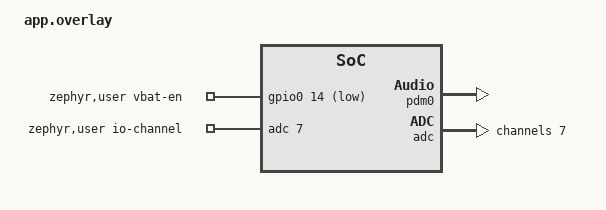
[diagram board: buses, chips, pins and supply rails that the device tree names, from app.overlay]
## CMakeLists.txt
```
cmake_minimum_required(VERSION 3.20.0)
find_package(Zephyr REQUIRED HINTS $ENV{ZEPHYR_BASE})
project(meowtion_collar)

target_sources(app PRIVATE
    src/main.c
    src/ble.c
    src/audio.c
    src/streaming.c
    src/battery.c
    src/classifier.c
    src/activity.c              # rules-based activity gate (cascade tier 0): low-power rest gating
    src/production.c            # production mode: real on-device classification -> telemetry
    src/imu.c
    src/ota.c                   # Phase-3 OTA model delivery: BLE -> flash slots -> XIP load
    src/tflm_classifier.cpp)   # TFLM inference backend , strong overrides of the cascade hooks
target_include_directories(app PRIVATE ${CMAKE_CURRENT_SOURCE_DIR}/../common)   # shared meow_protocol.h
```

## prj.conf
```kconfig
# Meowtion collar (Zephyr / nRF Connect SDK)
CONFIG_BT=y
CONFIG_BT_PERIPHERAL=y            # connectable: a central (station/phone) connects to stream audio
CONFIG_BT_DEVICE_NAME="Meowtion Collar"
CONFIG_LOG=y

# Throughput for the audio notify stream: bigger ATT MTU + link-layer data length.
CONFIG_BT_L2CAP_TX_MTU=247
CONFIG_BT_BUF_ACL_TX_SIZE=251
CONFIG_BT_BUF_ACL_RX_SIZE=251
CONFIG_BT_CTLR_DATA_LENGTH_MAX=251
CONFIG_BT_GATT_AUTO_UPDATE_MTU=y
# The 8 kHz stream is ~17 KB/s. At 1 packet per connection event the link sat just under that and
# slowly dropped frames. Queue several packets per event (more TX buffers; the controller's event-RX
# count must stay above the ACL-TX count) and enable 2M PHY (half the airtime per packet) so the
# drain rate clears the audio rate with margin. Station requests 2M after connecting.
CONFIG_BT_BUF_ACL_TX_COUNT=10
CONFIG_BT_BUF_EVT_RX_COUNT=12
CONFIG_BT_CTLR_PHY_2M=y

# --- BLE link security (LE Secure Connections) ---
# The audio + OTA characteristics require an ENCRYPTED link (see ble.c/ota.c PERM_*_ENCRYPT), so an
# unpaired central cannot stream audio or push a model. NON-BONDABLE on purpose: a battery collar
# reboots often, so a stored bond would go stale and pairing would then fail until both sides re-sync.
# Pairing fresh each connection (a sub-second ECDH; SMP pulls in CONFIG_BT_ECC / P-256) stores nothing,
# so there is no bond state to go stale. Just Works today; step 2b adds a USB-provisioned OOB secret
# that authenticates each pairing (MITM protection).
CONFIG_BT_SMP=y
CONFIG_BT_BONDABLE=n

# USB CDC ACM console + the MEOW> id banner, on the LEGACY USB device stack.
# The board's default backend uses the new (NEXT) USB stack, whose CDC console doesn't deliver
# console output on this build (the port enumerates but stays silent). So we disable the board
# backend and bring up a single legacy CDC ACM ourselves (see app.overlay + usb_enable() in
# main). The legacy stack's console poll_out buffers reliably, which is what we need.
CONFIG_BOARD_SERIAL_BACKEND_CDC_ACM=n
CONFIG_USB_DEVICE_STACK=y
CONFIG_USB_DEVICE_PRODUCT="Meowtion Collar"
CONFIG_SERIAL=y
CONFIG_UART_LINE_CTRL=y
CONFIG_CONSOLE=y
CONFIG_UART_CONSOLE=y

# Real battery sensing: ADC (SAADC) on AIN7 + GPIO to gate the divider (see app.overlay).
CONFIG_ADC=y
CONFIG_GPIO=y

# Onboard PDM microphone (XIAO Sense) for audio capture.
CONFIG_AUDIO=y
CONFIG_AUDIO_DMIC=y

# Onboard IMU (LSM6DS3TR-C on i2c0, driven by Zephyr's lsm6dsl driver). Sampled alongside each
# audio clip to produce paired training data, and fed to the classifier cascade. Polled (no trigger).
CONFIG_I2C=y
CONFIG_SENSOR=y
CONFIG_LSM6DSL=y
# The IMU sensor node is marked zephyr,deferred-init (overlay) so its init runs from imu_init()
# in main , after the power rail is up , instead of at boot where it raced the rail and failed.

# On-collar inference: TensorFlow Lite Micro (C++17). No model is compiled in , models are loaded at
# runtime (model_loader.h), so present()==false until then and the cascade runs model-free. TFLM's
# Kconfig selects REQUIRES_FULL_LIBCPP. CMSIS-NN kernels are optimized Cortex-M ops (cmsis-nn is
# allowlisted in the NCS manifest) , they accelerate Conv/FullyConnected/Pooling/Softmax.
CONFIG_CPP=y
CONFIG_STD_CPP17=y
CONFIG_TENSORFLOW_LITE_MICRO=y
CONFIG_TENSORFLOW_LITE_MICRO_CMSIS_NN_KERNELS=y

# Phase-3 OTA model delivery (src/ota.c): receive a .tflite over BLE, stage it into the
# models_storage flash partition (see pm_static.yml), verify CRC, and run it in place (XIP).
# FLASH/FLASH_MAP expose the partition; STREAM_FLASH does the page-buffered receive into flash;
# STREAM_FLASH_ERASE makes it erase each model page as it streams (so we don't block the BT thread
# erasing the whole slot up front - that ~4 s stall on the 192 KB slot would trip the link's
# supervision timeout); FLASH_PAGE_LAYOUT lets stream_flash erase by page; CRC provides crc32_ieee().
# The internal flash driver (CONFIG_SOC_FLASH_NRF) is default-on for this SoC.
CONFIG_FLASH=y
CONFIG_FLASH_MAP=y
CONFIG_FLASH_PAGE_LAYOUT=y
CONFIG_STREAM_FLASH=y
CONFIG_STREAM_FLASH_ERASE=y
CONFIG_CRC=y

# On-device inference (TFLite-Micro AllocateTensors + Invoke) runs on the MAIN thread - both at boot
# (ota_load_stored_models) and every cycle (production.c). TFLM's call chains need far more stack
# than the ~2 KB default; with too little it overflows and the collar faults/reboot-loops the moment
# a model is loaded. Give main a generous stack.
CONFIG_MAIN_STACK_SIZE=16384
```

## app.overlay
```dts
/*
 * Real battery sensing for the XIAO nRF52840.
 * The battery sits behind a divider on P0.31 (AIN7); P0.14 must be driven LOW to connect it.
 * We model that as an ADC channel plus an enable GPIO under /zephyr,user.
 */
#include <zephyr/dt-bindings/adc/adc.h>
#include <zephyr/dt-bindings/adc/nrf-saadc.h>
#include <zephyr/dt-bindings/gpio/gpio.h>

/ {
	zephyr,user {
		io-channels = <&adc 7>;                          /* AIN7 = P0.31 = battery / divider */
		vbat-en-gpios = <&gpio0 14 GPIO_ACTIVE_LOW>;     /* P0.14 LOW connects the divider */
	};

	/* power the onboard PDM microphone at boot (XIAO Sense) so we can capture audio */
	msm261d3526hicpm-c-en {
		regulator-boot-on;
	};
};

/* the onboard PDM mic (MSM261D3526H1CPM) , enable it and give it a label for DEVICE_DT_GET */
dmic_dev: &pdm0 {
	status = "okay";
};

/*
 * IMU power rail timing fix.
 * The LSM6DS3TR-C needs ~15 ms after power-on before it answers on I2C (datasheet boot time).
 * The board's enable regulator defaults to a 3 ms startup delay, so the sensor driver's first
 * I2C read at boot lands while the chip is still booting and init fails ("Failed to initialize
 * chip" -> "LSM6DS3TR-C not ready"). Extend the rail's settle time so power is stable before the
 * driver probes, and keep it always-on so it is never treated as an unused regulator and dropped.
 */
&{/lsm6ds3tr-c-en} {
	startup-delay-us = <20000>;
	regulator-always-on;
};

/* Defer the IMU driver's init out of the boot sequence so imu_init() can run it from main, after
 * the rail is powered and settled (see src/imu.c). Auto-init at boot was racing the power rail. */
&lsm6ds3tr_c {
	zephyr,deferred-init;
};

&adc {
	#address-cells = <1>;
	#size-cells = <0>;

	channel@7 {
		reg = <7>;
		zephyr,gain = "ADC_GAIN_1_6";                    /* full-scale 3.6 V at the pin */
		zephyr,reference = "ADC_REF_INTERNAL";           /* 0.6 V internal ref */
		zephyr,acquisition-time = <ADC_ACQ_TIME(ADC_ACQ_TIME_MICROSECONDS, 20)>;
		zephyr,input-positive = <NRF_SAADC_AIN7>;
		zephyr,resolution = <12>;
	};
};
```

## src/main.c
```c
/*
 * Meowtion collar firmware (Zephyr / nRF Connect SDK, XIAO nRF52840 Sense).
 *
 * The collar is BLE-only: it senses on the cat and runs ONE connectable advertisement carrying a
 * small telemetry packet plus a custom audio service. A station (ESP32) reads the telemetry and,
 * when it connects + subscribes, the collar streams paired audio + IMU for training-data capture.
 * The collar never touches WiFi/internet , that keeps it tiny and low-power.
 *
 * Module split:
 *   ble.c        advertising, identity, the audio GATT service, notify
 *   audio.c      PDM mic capture -> 8 kHz µ-law
 *   streaming.c  the decoupled reader/sender threads that assemble + send frames
 *   battery.c    1S LiPo charge via the onboard divider
 *   imu.c        LSM6DS3TR-C continuous sampler   (unchanged)
 *   classifier.c the confidence-gated action cascade (weak stubs until a model lands; unchanged)
 *
 * Telemetry packet (manufacturer-specific AD data, 8 bytes). The version byte [2] tells the station
 * which of two contracts is in force:
 *
 *   version = 1  SIMULATED (pre-training fallback, update_telemetry_sim() below):
 *     [2]=1  [3] state(0..5)  [4] activity(0..100)  [5..6] steps LE  [7] battery
 *
 *   version = 2  REAL ON-DEVICE CLASSIFICATION (production.c, runs once a model is present):
 *     [2]=2  [3] class INDEX (0..N-1) into the model's label table, or 0xFF = UNKNOWN/low-confidence
 *     [4] confidence 0..100 (round(confidence*100))  [5..6] steps LE  [7] battery
 *
 * The collar's BLE address identifies which collar it is (no id needed in the payload).
 *
 * PRODUCTION vs SIMULATED is chosen each cycle by production_active() (a trained IMU model is linked
 * AND we are not in a training-capture stream). With no model the simulated state machine runs and
 * version stays 1; once a model lands, real IMU classification drives the telemetry and version is 2.
 */
#include <zephyr/kernel.h>
#include <zephyr/bluetooth/bluetooth.h>
#include <zephyr/random/random.h>
#include <zephyr/logging/log.h>
#include <zephyr/usb/usb_device.h>
#include <zephyr/drivers/uart.h>

#include "ble.h"
#include "audio.h"
#include "battery.h"
#include "imu.h"
#include "classifier.h"
#include "activity.h"
#include "production.h"
#include "ota.h"

LOG_MODULE_REGISTER(collar, LOG_LEVEL_INF);

/* state: 0 sleep, 1 rest, 2 active, 3 walk, 4 play, 5 groom */
static uint8_t  g_state = 1;
static uint16_t g_steps = 0;
static uint8_t  g_battery = 96;
static int64_t  g_state_until = 0;       /* uptime (ms) at which the current state ends */

/* per-state dwell range (seconds) and a typical activity level (0..100). A cat holds a
 * behaviour for a realistic spell instead of flickering every packet, so the station relays
 * sensible episodes. (Placeholder until real IMU classification.) */
static const uint16_t DUR_MIN[6] = {  60, 40, 20, 20, 20, 20 };
static const uint16_t DUR_MAX[6] = { 180, 120, 60, 40, 50, 40 };
static const uint8_t  ACT[6]     = {   2, 12, 55, 45, 80, 30 };

/* SIMULATED telemetry (version = 1) , the pre-training fallback. Runs only while no trained model is
 * present; once a model lands, production_update_telemetry() (version = 2) replaces it. Real
 * IMU-based classification lives in production.c / classifier.c. Left intact and unchanged. */
static void update_telemetry_sim(void)
{
    int64_t now = k_uptime_get();

    /* hold each behaviour for a realistic dwell, then transition to a new one */
    if (now >= g_state_until) {
        g_state = sys_rand32_get() % 6;
        uint32_t secs = DUR_MIN[g_state] + (sys_rand32_get() % (DUR_MAX[g_state] - DUR_MIN[g_state] + 1));
        g_state_until = now + (int64_t)secs * 1000;
    }

    if (g_state >= 2 && g_state <= 4) {              /* moving: steps accrue */
        g_steps += 1 + sys_rand32_get() % 4;
    }
    g_battery = read_battery();          /* real pack charge (rises on USB charge) */

    int act = (int)ACT[g_state] + ((int)(sys_rand32_get() % 11) - 5);   /* jitter +/-5 */
    if (act < 0) act = 0; else if (act > 100) act = 100;

    uint8_t *mfg = ble_mfg_data();
    mfg[2] = 1;                          /* version 1 = simulated (pre-training fallback) */
    mfg[3] = g_state;
    mfg[4] = (uint8_t)act;
    mfg[5] = g_steps & 0xFF;
    mfg[6] = (g_steps >> 8) & 0xFF;
    mfg[7] = g_battery;
}

/* Telemetry class byte (version=2 packet) meaning "collar is in low-power rest". Distinct from a
 * model class index (0..N-1) and from 0xFF=UNKNOWN; the station maps it to a "rest" episode so the
 * whole dormant span becomes one rest event. */
#define TELEM_REST  0xFE

/* Cascade TIER 0 , low-power rest. Entered from the production branch once the rules-based activity
 * gate (activity.c) sees sustained stillness. Stops the 104 Hz stream + inference, drops the IMU to
 * a low-power watch ODR, slows the radio, and advertises a REST beacon so the station opens a rest
 * episode. Polls the IMU slowly for motion; on motion it restores active operation and returns, and
 * the next production cycle re-advertises a real class so the station closes the rest episode (the
 * rest event covering the dormant span). Leaves early if a central connects or a capture starts so
 * the normal loop can service it. */
static void enter_low_power_rest(void)
{
    LOG_INF("activity: still >= %us , entering low-power rest", ACT_REST_HOLDOFF_S);

    production_yield();              /* stop the 104 Hz stream + drop the inference window */
    imu_set_lowpower(true);         /* low-power watch ODR */
    ble_set_adv_slow(true);         /* slow the radio */

    /* Advertise the REST beacon (version=2, class=REST) so the station logs the rest episode. */
    uint8_t *mfg = ble_mfg_data();
    mfg[2] = 2;
    mfg[3] = TELEM_REST;
    mfg[4] = 0;
    mfg[7] = read_battery();
    if (!ble_is_connected()) { ble_start_adv(); ble_update_adv(); }

    const int64_t t0 = k_uptime_get();
    int64_t last_beacon = t0;
    while (1) {
        if (ble_is_connected() || ble_streaming_enabled()) break;   /* let the main loop service it */
        if (imu_motion_mg() >= ACT_WAKE_MG) break;                  /* motion , wake */
        int64_t now = k_uptime_get();
        if (now - last_beacon >= 12000) {       /* refresh < the station's 30 s stale window */
            mfg[7] = read_battery();
            ble_start_adv();
            ble_update_adv();
            last_beacon = now;
        }
        k_sleep(K_MSEC(500));                   /* SoC idles between polls */
    }

    LOG_INF("activity: motion , waking after %llus rest",
            (unsigned long long)((k_uptime_get() - t0) / 1000));
    imu_set_lowpower(false);        /* restore the classification sampling rate */
    ble_set_adv_slow(false);        /* restore the fast advertising interval */
    activity_reset();
    /* the next loop iteration restarts production (imu_stream_start) and resumes classification. */
}

int main(void)
{
    /* Bring up USB so the CDC ACM console (the COM port) works, then wait up to ~3 s for a
     * serial terminal to attach (DTR) so boot logs aren't lost. We never block forever , the
     * collar must advertise even with no USB host attached. */
    if (usb_enable(NULL) == 0) {
        const struct device *con = DEVICE_DT_GET(DT_CHOSEN(zephyr_console));
        uint32_t dtr = 0;
        for (int i = 0; i < 30 && !dtr; i++) {
            uart_line_ctrl_get(con, UART_LINE_CTRL_DTR, &dtr);
            k_sleep(K_MSEC(100));
        }
    }

    battery_init();
    audio_mic_init();
    clf_init();                  /* action-classifier cascade (runs model-free until models land) */
    ota_load_stored_models();    /* re-load any previously-OTA'd model from flash so it's live now */
    if (!imu_init())             /* LSM6DS3TR-C; sampled alongside each clip + fed to the cascade */
        LOG_ERR("IMU init FAILED , clips will upload audio-only (no paired motion data)");

    int err = bt_enable(NULL);
    if (err) {
        LOG_ERR("bt_enable failed (%d)", err);
        return 0;
    }

    ble_compute_id();
    ble_start_adv();             /* connectable: telemetry beacon + audio service */
    LOG_INF("collar advertising (connectable), id=%s", ble_id());

    while (1) {
        /* Finish loading any OTA-delivered model here, on the main thread's big stack (clf_set is too
         * stack-heavy for the BLE-RX callback). No-op when nothing is pending. */
        ota_service_loads();

        /* Two clear branches. PRODUCTION (a trained IMU model is linked AND we're not in a capture
         * stream): run real on-device classification on a rolling IMU window and emit the version=2
         * packet. Otherwise fall back to the SIMULATED state machine (version=1). During a capture
         * stream we do neither , streaming.c owns the IMU + mic to build training clips. */
        if (production_active()) {
            production_update_telemetry();
            /* Cascade tier 0: if the cat has been still past the hold-off, drop to low-power rest
             * until motion returns. This is the main battery lever , no 104 Hz sampling, no
             * inference, and a slow radio while the cat is resting. */
            if (activity_should_rest(production_peak_mg(), 2)) {
                enter_low_power_rest();
            }
        } else {
            production_yield();          /* release our IMU ownership so capture/re-entry is clean */
            update_telemetry_sim();
        }

        /* Ensure we're advertising whenever not connected. This self-heals the re-advertise after
         * a capture disconnects (restarting adv from the disconnect callback is unreliable), so the
         * station can reconnect for the next clip. While connected, advertising is off , skip it. */
        if (!ble_is_connected()) {
            ble_start_adv();
            ble_update_adv();
        }
        /* Identity banner the dashboard reads over USB serial to register this collar. */
        printk("MEOW> collar id=%s\n", ble_id());
        /* Log the values that are actually live this cycle: the simulated globals are only updated in
         * the simulated branch, so logging them in production mode would print frozen numbers. */
        if (production_active()) {
            LOG_INF("production: peak=%umg stream=%d",
                    production_peak_mg(), ble_streaming_enabled());
        } else {
            LOG_INF("sim: state=%u steps=%u batt=%u stream=%d",
                    g_state, g_steps, g_battery, ble_streaming_enabled());
        }
        k_sleep(K_SECONDS(2));   /* TODO: wake-on-motion deep sleep for battery life */
    }
    return 0;
}
```

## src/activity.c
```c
/* Rules-based activity gate (cascade tier 0). See activity.h. Pure still-timer policy. */
#include "activity.h"

/* Accumulated seconds the cat has been continuously "still". Reset by motion or activity_reset(). */
static uint32_t g_still_s;

void activity_reset(void) { g_still_s = 0; }

bool activity_should_rest(uint32_t peak_mg, uint32_t dt_s)
{
	if (peak_mg >= ACT_STILL_MG) {   /* any real motion restarts the hold-off */
		g_still_s = 0;
		return false;
	}
	g_still_s += dt_s;
	return g_still_s >= ACT_REST_HOLDOFF_S;
}
```

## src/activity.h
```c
/*
 * Rules-based activity gate , cascade TIER 0 (runs before the model-based tiers).
 *
 * The model tiers (IMU CNN, then audio CNN) are only worth running while the cat is actually doing
 * something. Most of a cat's day is rest/sleep, and classifying stillness 50 times a second drains
 * the cell for no information. This tier is a cheap motion-energy rule that decides "active vs
 * resting" with no model at all:
 *
 *   active  -> hand off to the model cascade (production.c / classifier.c) as usual.
 *   resting -> sustained low motion past a hold-off drops the collar into low-power rest (main.c):
 *              the 104 Hz stream and inference stop, the IMU drops to a low-power watch ODR, and the
 *              radio slows. A motion event ends rest, and the station logs the whole dormant span as
 *              a single rest episode (the "rest event").
 *
 * This module is pure policy (a still-timer over a motion-energy proxy). main.c owns the hardware
 * power transitions and the low-power motion watch; production.c feeds the per-cycle motion proxy.
 */
#pragma once
#include <stdbool.h>
#include <stdint.h>

/* Peak accel-magnitude deviation from 1 g (milli-g) at or below which a cycle counts as "still".
 * A resting cat sits near 1 g (deviation ~0); small grooming/shuffles stay under this. */
#define ACT_STILL_MG        150u
/* Sustained-still time (seconds) before the gate drops the collar to low-power rest. */
#define ACT_REST_HOLDOFF_S   60u
/* Motion (mg deviation) during the rest watch that ends rest and re-arms the model cascade. */
#define ACT_WAKE_MG         220u

/* Forget any accumulated stillness (call on waking, or when entering production). */
void activity_reset(void);

/* Feed one active cycle: peak motion this cycle (mg deviation from 1 g) and the seconds elapsed
 * since the previous call. Returns true once stillness has persisted past ACT_REST_HOLDOFF_S, i.e.
 * the collar should enter low-power rest. */
bool activity_should_rest(uint32_t peak_mg, uint32_t dt_s);
```

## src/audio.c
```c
/*
 * Onboard PDM microphone (XIAO Sense) , capture + model-rate conversion. See audio.h.
 *
 * Captures short clips for eat/drink labelling. 8 kHz is plenty for crunch vs lap and halves the
 * BLE data, so clips are small and transfer fast (lets us record back-to-back with no gap).
 *
 * The nRF52840 PDM block CANNOT produce 8 kHz natively: its slowest clock (~1 MHz / 64 decimation)
 * floors at ~15.6 kHz, so asking the driver for 8 kHz silently yields ~16 kHz (configure still
 * "succeeds"). That made clips play back at half speed and doubled the link throughput (the click).
 * So we capture at the real 16 kHz and decimate 2:1 in software (pairwise average = a cheap
 * anti-alias low-pass) to a genuine 8 kHz wire stream.
 */
#include "audio.h"
#include "audio_codec.h"   /* ulaw_encode , shared with the inference preprocessing */

#include <zephyr/kernel.h>
#include <zephyr/device.h>
#include <zephyr/audio/dmic.h>
#include <zephyr/logging/log.h>

LOG_MODULE_REGISTER(audio, LOG_LEVEL_INF);

#define MIC_CAP_RATE    16000                         /* PDM hardware native rate (decimated 2:1) */
#define MIC_BITS        16
#define MIC_CAP_BYTES   (2 * (MIC_CAP_RATE / 10))     /* 100 ms @ 16 kHz = one DMA block */

/* The reader thread drains this every 100 ms straight into the TX queue and never blocks on BLE, so
 * the slab stays near-empty , a few blocks of jitter headroom is plenty (the BLE backlog now lives
 * in the much larger tx_q instead). 8 blocks = ~0.8 s, and freeing the old deep slab leaves RAM for
 * the frame queue. */
#define MIC_BLOCKS      8
K_MEM_SLAB_DEFINE_STATIC(mic_slab, MIC_CAP_BYTES, MIC_BLOCKS, 4);
static const struct device *mic_dev = DEVICE_DT_GET(DT_NODELABEL(dmic_dev));
static bool g_mic_ready = false;

void audio_mic_init(void)
{
    if (!device_is_ready(mic_dev)) { LOG_ERR("mic not ready"); return; }
    struct pcm_stream_cfg stream = { .pcm_width = MIC_BITS, .mem_slab = &mic_slab };
    struct dmic_cfg cfg = {
        .io = { .min_pdm_clk_freq = 1000000, .max_pdm_clk_freq = 3500000,
                .min_pdm_clk_dc = 40, .max_pdm_clk_dc = 60 },
        .streams = &stream,
        .channel = { .req_num_streams = 1, .req_num_chan = 1 },
    };
    cfg.channel.req_chan_map_lo = dmic_build_channel_map(0, 0, PDM_CHAN_LEFT);
    cfg.streams[0].pcm_rate = MIC_CAP_RATE;        /* native 16 kHz; decimated to MIC_RATE on read */
    cfg.streams[0].block_size = MIC_CAP_BYTES;
    if (dmic_configure(mic_dev, &cfg) < 0) { LOG_ERR("dmic configure failed"); return; }
    g_mic_ready = true;
    LOG_INF("mic ready");
}

bool audio_mic_ready(void) { return g_mic_ready; }

void audio_stream_start(void)
{
    /* settle the PDM filter ONCE at stream start (avoids the click) by discarding a few blocks. */
    for (int skip = 0; skip < 4; skip++) {
        void *sb; uint32_t sz;
        if (dmic_read(mic_dev, 0, &sb, &sz, 500) >= 0) k_mem_slab_free(&mic_slab, sb);
    }
}

/* Start the PDM. Returns the dmic_trigger result (0 = ok). Kept separate from audio_stream_start so
 * the reader can bail before the settle-skip if the trigger fails. */
int audio_trigger_start(void)
{
    return dmic_trigger(mic_dev, DMIC_TRIGGER_START);
}

void audio_stream_stop(void)
{
    dmic_trigger(mic_dev, DMIC_TRIGGER_STOP);
}

int audio_read_ulaw(uint8_t *dst, uint32_t max_bytes)
{
    void *buf; uint32_t size;
    if (dmic_read(mic_dev, 0, &buf, &size, 500) < 0) return -1;

    /* Decimate 2:1 (16 kHz -> 8 kHz) out of the DMA slab, then µ-law encode to 8-bit so each
     * sample is one byte (half the wire data). Averaging adjacent samples is a cheap
     * anti-alias low-pass. Free the slab IMMEDIATELY once read. */
    if (size > MIC_CAP_BYTES) size = MIC_CAP_BYTES;
    const int16_t *src = (const int16_t *)buf;
    uint32_t out_n = (size / 2) / 2;                 /* 16 kHz samples / 2 -> 8 kHz */
    if (out_n > max_bytes) out_n = max_bytes;
    for (uint32_t i = 0; i < out_n; i++) {
        int16_t s = (int16_t)(((int32_t)src[2 * i] + src[2 * i + 1]) / 2);
        dst[i] = ulaw_encode(s);                     /* 16-bit PCM -> 8-bit µ-law */
    }
    k_mem_slab_free(&mic_slab, buf);
    return (int)out_n;                               /* one µ-law byte per sample */
}
```

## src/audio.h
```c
/*
 * Onboard PDM microphone (XIAO Sense) , capture + model-rate conversion.
 *
 * Captures at the PDM's real 16 kHz, decimates 2:1 to 8 kHz, and µ-law-encodes to one byte per
 * sample , the exact representation the model trains on and the stream sends. The streaming reader
 * drives start/stop and pulls one 100 ms chunk per frame; everything PDM-specific stays here.
 */
#pragma once
#include <stdint.h>
#include <stdbool.h>

#define MIC_RATE        8000                          /* wire/output rate (what we send + label) */
#define MIC_BLOCK_BYTES (2 * (MIC_RATE / 10))         /* 100 ms @ 8 kHz, 16-bit = one wire frame */

/* Configure the PDM mic. Safe to call once at boot; sets the ready flag on success. */
void audio_mic_init(void);

/* True once the mic is configured and can be triggered. */
bool audio_mic_ready(void);

/* Start the PDM hardware. Returns 0 on success (non-zero = trigger failed, caller should retry). */
int audio_trigger_start(void);

/* Discard a few blocks so the decimation/PDM filter settles once (avoids the start-of-stream
 * click). Call after a successful audio_trigger_start(), before the first audio_read_ulaw(). */
void audio_stream_start(void);

/* End the capture session (stop the PDM). */
void audio_stream_stop(void);

/* Read the next 100 ms of audio as 8 kHz µ-law (one byte per sample): blocks for one DMA block at
 * 16 kHz, decimates 2:1, and µ-law-encodes into dst. Returns the number of µ-law bytes written, or
 * -1 on a read error (the caller should end the session). dst must hold MIC_BLOCK_BYTES/2 bytes. */
int audio_read_ulaw(uint8_t *dst, uint32_t max_bytes);
```

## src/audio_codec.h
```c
/*
 * Audio representation shared by training-data capture and on-collar inference , the single source
 * of truth so the two can never drift apart.
 *
 * Training clips travel: PDM 16 kHz -> decimate 2:1 to 8 kHz -> µ-law (8-bit) over BLE -> the station
 * decodes µ-law back to 16-bit PCM and stores a WAV. So the audio-confirm model trains on 8 kHz audio
 * that has been through a µ-law round-trip.
 *
 * For the on-collar audio stage (clf_classify, stage 2) to see the SAME distribution at inference as
 * it saw in training, run live mic audio through audio_to_model_pcm() before handing it to the
 * cascade. A train/inference representation mismatch costs far more accuracy than the µ-law noise
 * floor itself, so everything funnels through here.
 */
#pragma once
#include <stdint.h>
#include <stddef.h>
#include "meow_protocol.h"   /* ulaw_encode/ulaw_decode + the wire format , shared with the station */

#define MODEL_AUDIO_RATE_HZ 8000   /* the rate the audio model trains and infers at */

/*
 * Convert a raw 16 kHz PDM window to the model's audio representation: 8 kHz, µ-law-companded 16-bit,
 * i.e. EXACTLY what a training clip became. Decimate 2:1 (pairwise average = a cheap anti-alias
 * low-pass), then a µ-law encode+decode round-trip to impose the same 8-bit quantization the training
 * audio carries. Writes up to out_cap samples to out8k; returns the number of 8 kHz samples produced.
 *
 *   in16k / in_n : raw 16 kHz int16 samples captured live on the collar
 *   out8k        : model-ready 8 kHz int16 samples (pass to clf_classify as pcm/pcm_len)
 */
static inline size_t audio_to_model_pcm(const int16_t *in16k, size_t in_n,
                                        int16_t *out8k, size_t out_cap)
{
	size_t out_n = in_n / 2;
	if (out_n > out_cap) out_n = out_cap;
	for (size_t i = 0; i < out_n; i++) {
		int16_t s = (int16_t)(((int32_t)in16k[2 * i] + in16k[2 * i + 1]) / 2);
		out8k[i] = ulaw_decode(ulaw_encode(s));   /* same 8-bit µ-law quantization as training */
	}
	return out_n;
}
```

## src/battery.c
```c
/*
 * Battery sensing , 1S LiPo charge via the XIAO's onboard divider. See battery.h.
 *
 * AIN7 (P0.31) reads the pack through a 1M/510k divider; P0.14 gates it (active-low) so the divider
 * only bleeds current during a measurement (see app.overlay).
 */
#include "battery.h"

#include <zephyr/kernel.h>
#include <zephyr/drivers/adc.h>
#include <zephyr/drivers/gpio.h>
#include <zephyr/logging/log.h>

LOG_MODULE_REGISTER(battery, LOG_LEVEL_INF);

/* Voltage divider on the XIAO: VBAT -> 1M (top) / 510k (bottom) -> AIN7. Pin mV * (R_top+R_bot)/R_bot
 * recovers pack mV. */
#define VBAT_DIV_TOP_K   1000
#define VBAT_DIV_BOT_K   510
/* 1S LiPo percent is a crude LINEAR map (not a real state-of-charge curve): 3.0 V = 0%, 4.2 V = 100%. */
#define BATT_MV_EMPTY    3000
#define BATT_MV_FULL     4200

static const struct adc_dt_spec  vbat_adc = ADC_DT_SPEC_GET_BY_IDX(DT_PATH(zephyr_user), 0);
static const struct gpio_dt_spec vbat_en  = GPIO_DT_SPEC_GET(DT_PATH(zephyr_user), vbat_en_gpios);

/* Last good reading, returned on a sensor error. Seeds the telemetry default before the first read. */
static uint8_t last_pct = 96;

void battery_init(void)
{
    if (gpio_is_ready_dt(&vbat_en)) gpio_pin_configure_dt(&vbat_en, GPIO_OUTPUT_INACTIVE);  /* divider off */
    if (adc_is_ready_dt(&vbat_adc)) adc_channel_setup_dt(&vbat_adc);
}

uint8_t read_battery(void)
{
    if (!adc_is_ready_dt(&vbat_adc)) return last_pct;

    gpio_pin_set_dt(&vbat_en, 1);          /* assert (active-low) => P0.14 low => divider on */
    k_sleep(K_MSEC(10));

    int16_t raw = 0;
    struct adc_sequence seq = { .buffer = &raw, .buffer_size = sizeof(raw), .calibrate = true };
    int err = adc_sequence_init_dt(&vbat_adc, &seq);
    if (!err) err = adc_read_dt(&vbat_adc, &seq);

    gpio_pin_set_dt(&vbat_en, 0);          /* divider off again (saves the ~3 uA bleed) */
    if (err) { LOG_WRN("battery adc err %d", err); return last_pct; }

    int32_t mv = raw;
    adc_raw_to_millivolts_dt(&vbat_adc, &mv);   /* mV at the ADC pin */
    int vbat = mv * (VBAT_DIV_TOP_K + VBAT_DIV_BOT_K) / VBAT_DIV_BOT_K;   /* undo the 1M/510k divider */
    int pct = (vbat - BATT_MV_EMPTY) * 100 / (BATT_MV_FULL - BATT_MV_EMPTY);  /* percent (linear) */
    last_pct = pct < 0 ? 0 : (pct > 100 ? 100 : pct);
    return last_pct;
}
```

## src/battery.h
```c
/*
 * Battery sensing , 1S LiPo charge via the XIAO's onboard divider.
 *
 * The pack sits behind a 1M/510k divider on AIN7 (P0.31), gated by an enable GPIO (P0.14) so the
 * divider only draws current while we measure. This module owns the ADC + GPIO; main just reads a
 * percentage each telemetry cycle.
 */
#pragma once
#include <stdint.h>

/* Configure the battery ADC channel and the divider-enable GPIO (divider left off). */
void battery_init(void);

/* Sample the pack and return charge 0..100 (1S LiPo: 3.0 V = 0%, 4.2 V = 100%). Returns the last
 * known value on error. Rises while charging over USB (charging raises the pack voltage). */
uint8_t read_battery(void);
```

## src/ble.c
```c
/*
 * BLE link , advertising, identity, and the audio GATT service. See ble.h.
 *
 * One connectable advertisement carries the telemetry packet AND exposes a custom audio service.
 * advertising auto-stops while connected and the main loop resumes it on disconnect (restarting it
 * from the disconnect callback is unreliable).
 */
#include "ble.h"

#include <zephyr/bluetooth/bluetooth.h>
#include <zephyr/bluetooth/conn.h>
#include <zephyr/bluetooth/gatt.h>
#include <zephyr/bluetooth/uuid.h>
#include <zephyr/sys/util.h>
#include <zephyr/logging/log.h>

LOG_MODULE_REGISTER(ble, LOG_LEVEL_INF);

#define COMPANY_ID 0xFFFF        /* SIG test/"no company" id */

/* Telemetry packet (manufacturer-specific AD data, 8 bytes). main() fills [3..7] each cycle. */
static uint8_t mfg[8] = { COMPANY_ID & 0xFF, (COMPANY_ID >> 8) & 0xFF, 1, 1, 0, 0, 0, 96 };

/* Identity the dashboard registers and the station relays. Derived from the BLE address the
 * SAME way the station does (cat_<addr[2]><addr[1]><addr[0]>), so the two always agree. */
static char g_id[16] = "cat_000000";

void ble_compute_id(void)
{
    bt_addr_le_t addrs[CONFIG_BT_ID_MAX];
    size_t count = ARRAY_SIZE(addrs);
    bt_id_get(addrs, &count);
    if (count > 0) {
        const uint8_t *v = addrs[0].a.val;     /* little-endian */
        snprintk(g_id, sizeof g_id, "cat_%02x%02x%02x", v[2], v[1], v[0]);
    }
}

const char *ble_id(void) { return g_id; }

uint8_t *ble_mfg_data(void) { return mfg; }

static struct bt_data ad[] = {
    BT_DATA_BYTES(BT_DATA_FLAGS, BT_LE_AD_NO_BREDR),
    BT_DATA(BT_DATA_MANUFACTURER_DATA, mfg, sizeof(mfg)),
};

/* ---------------- BLE audio service (stream the mic when a central connects) ----------------
 * Custom 128-bit service with one NOTIFY characteristic. When a central (the station, or a phone
 * for testing) connects and enables notifications, the stream thread sends µ-law audio frames as
 * notifications. The collar keeps a CONNECTABLE advert carrying the telemetry packet (identity
 * address, so the id stays stable); advertising auto-stops while connected and resumes on disconnect. */
#define MEOW_SVC_UUID   BT_UUID_128_ENCODE(0x4d656f77, 0x0a01, 0x4175, 0x6469, 0x6f0053657600)
#define MEOW_AUDIO_UUID BT_UUID_128_ENCODE(0x4d656f77, 0x0a02, 0x4175, 0x6469, 0x6f0043687200)
static struct bt_uuid_128 meow_svc_uuid   = BT_UUID_INIT_128(MEOW_SVC_UUID);
static struct bt_uuid_128 meow_audio_uuid = BT_UUID_INIT_128(MEOW_AUDIO_UUID);

static volatile bool   g_streaming = false;
static struct bt_conn *g_conn = NULL;

static void audio_ccc_changed(const struct bt_gatt_attr *attr, uint16_t value)
{
    ARG_UNUSED(attr);
    g_streaming = (value == BT_GATT_CCC_NOTIFY);
    LOG_INF("audio notifications %s", g_streaming ? "ON" : "off");
}

BT_GATT_SERVICE_DEFINE(meow_audio_svc,
    BT_GATT_PRIMARY_SERVICE(&meow_svc_uuid),
    BT_GATT_CHARACTERISTIC(&meow_audio_uuid.uuid, BT_GATT_CHRC_NOTIFY,
                           BT_GATT_PERM_NONE, NULL, NULL, NULL),
    /* Enabling notifications requires an ENCRYPTED link: an unpaired central cannot subscribe, so it
     * cannot receive the audio stream. (The station pairs first, then writes this CCC , see ble.c/ota.c.) */
    BT_GATT_CCC(audio_ccc_changed, BT_GATT_PERM_READ_ENCRYPT | BT_GATT_PERM_WRITE_ENCRYPT),
);

/* Fast interval for active use; slow (~1 s) for low-power rest. Both connectable + identity so the
 * collar stays reachable for capture/OTA and the station keeps relaying it. */
static const struct bt_le_adv_param adv_param_fast = BT_LE_ADV_PARAM_INIT(
    BT_LE_ADV_OPT_CONN | BT_LE_ADV_OPT_USE_IDENTITY,   /* connectable, keep the identity address */
    BT_GAP_ADV_FAST_INT_MIN_2, BT_GAP_ADV_FAST_INT_MAX_2, NULL);
static const struct bt_le_adv_param adv_param_slow = BT_LE_ADV_PARAM_INIT(
    BT_LE_ADV_OPT_CONN | BT_LE_ADV_OPT_USE_IDENTITY,
    BT_GAP_ADV_SLOW_INT_MIN, BT_GAP_ADV_SLOW_INT_MAX, NULL);   /* ~1 s: far less radio while resting */
static const struct bt_le_adv_param *g_adv = &adv_param_fast;

void ble_start_adv(void)
{
    int err = bt_le_adv_start(g_adv, ad, ARRAY_SIZE(ad), NULL, 0);
    if (err && err != -EALREADY) LOG_ERR("adv start failed (%d)", err);   /* -EALREADY = already on */
}

void ble_set_adv_slow(bool slow)
{
    g_adv = slow ? &adv_param_slow : &adv_param_fast;
    if (g_conn) return;                 /* advertising is off while connected; resumes on disconnect */
    (void)bt_le_adv_stop();             /* restart so the new interval takes effect */
    ble_start_adv();
}

void ble_update_adv(void)
{
    bt_le_adv_update_data(ad, ARRAY_SIZE(ad), NULL, 0);
}

bool ble_is_connected(void)    { return g_conn != NULL; }
bool ble_streaming_enabled(void) { return g_streaming; }

static void on_connected(struct bt_conn *conn, uint8_t err)
{
    if (err) { LOG_ERR("connect failed (0x%02x)", err); return; }
    g_conn = bt_conn_ref(conn);
    LOG_INF("central connected");
}
static void on_disconnected(struct bt_conn *conn, uint8_t reason)
{
    ARG_UNUSED(conn);
    LOG_INF("central disconnected (0x%02x)", reason);
    g_streaming = false;
    if (g_conn) { bt_conn_unref(g_conn); g_conn = NULL; }
    /* don't restart advertising here , doing it inside the disconnect callback is unreliable.
     * The main loop re-starts it (it ensures advertising whenever we're not connected). */
}
/* The station initiates pairing on connect; this reports whether an encrypted link came up.
 * level 2 = encrypted. */
static void on_security_changed(struct bt_conn *conn, bt_security_t level, enum bt_security_err err)
{
    ARG_UNUSED(conn);
    if (err) LOG_ERR("security failed: level %d (err %d)", level, err);
    else     LOG_INF("security changed: level %d (%s)", level,
                     level >= BT_SECURITY_L2 ? "ENCRYPTED" : "plaintext");
}
BT_CONN_CB_DEFINE(conn_cbs) = { .connected = on_connected, .disconnected = on_disconnected,
                                .security_changed = on_security_changed };

/* MTU-chunked notify of an arbitrary buffer on the audio characteristic. Returns 0 when the whole
 * buffer went out, or stops early (non-zero) if the central unsubscribed / disconnected. */
int ble_notify_frame(const uint8_t *p, uint32_t left)
{
    while (left > 0 && g_streaming) {
        uint16_t mtu = g_conn ? bt_gatt_get_mtu(g_conn) : 23;
        uint16_t chunk = (mtu > 3) ? (uint16_t)(mtu - 3) : 20;
        uint16_t n = (left < chunk) ? (uint16_t)left : chunk;
        int err = bt_gatt_notify(NULL, &meow_audio_svc.attrs[1], p, n);
        if (err == -ENOMEM || err == -EAGAIN || err == -ENOBUFS) { k_sleep(K_MSEC(2)); continue; }
        if (err) return err;             /* unsubscribed / disconnected */
        p += n; left -= n;
    }
    return (left == 0) ? 0 : -ECONNRESET;
}
```

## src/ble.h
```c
/*
 * BLE link , advertising, identity, and the audio GATT service.
 *
 * The collar runs ONE connectable advertisement that carries the telemetry packet (manufacturer
 * AD data) plus a custom 128-bit audio service with a single NOTIFY characteristic. A central (the
 * station, or a phone for testing) connects and subscribes; the streaming module then pushes audio
 * frames out through ble_notify_frame(). This module owns everything BLE: identity, the advert,
 * the service, the connection callbacks, and the MTU-chunked notify.
 */
#pragma once
#include <stdint.h>
#include <stdbool.h>

/* Compute the stable collar identity (cat_<addr[2]><addr[1]><addr[0]>) from the BLE address, the
 * SAME way the station derives it, so the two always agree. Call after bt_enable(). */
void ble_compute_id(void);

/* The collar identity string, e.g. "cat_a1b2c3". Valid after ble_compute_id(). */
const char *ble_id(void);

/* Start the connectable advert (telemetry beacon + audio service). Idempotent (-EALREADY is fine). */
void ble_start_adv(void);

/* Refresh the advertised manufacturer AD data after the telemetry bytes change. */
void ble_update_adv(void);

/* Switch the advertising interval: slow (true) for low-power rest, fast (false) for active use.
 * Restarts the advert with the chosen interval; a no-op on the radio while connected (advertising
 * is off then, and the next ble_start_adv picks up the current interval). */
void ble_set_adv_slow(bool slow);

/* True while a central is connected (advertising auto-stops while connected). */
bool ble_is_connected(void);

/* True while the central has notifications enabled, i.e. audio streaming is requested. */
bool ble_streaming_enabled(void);

/* The 8-byte manufacturer telemetry payload the advert carries. main writes into it each cycle:
 *   [0..1] company id   [2] version   [3] state   [4] activity   [5..6] steps LE   [7] battery */
uint8_t *ble_mfg_data(void);

/* MTU-chunked notify of one frame on the audio characteristic. Returns 0 when the whole buffer went
 * out, or non-zero if the central unsubscribed / disconnected partway. */
int ble_notify_frame(const uint8_t *p, uint32_t len);
```

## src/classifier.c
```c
/*
 * The confidence-gated cascade. See classifier.h for the design.
 *
 * Right now it runs model-free: the two inference hooks below are weak stubs that report "no
 * prediction", and the *_present() flags are false. The cascade still executes correctly , it just
 * always yields CLF_UNKNOWN, so the rest of the firmware (simulated telemetry, audio capture for
 * data collection) is unaffected.
 *
 * To add a model later:
 *   1. Provide a STRONG definition of imu_model_infer() (and/or audio_model_infer()) in a new file,
 *      e.g. wrapping TFLite-Micro or a generated inference function.
 *   2. Provide a STRONG clf_imu_model_present() (and/or audio) returning true.
 * The weak stubs here are then overridden automatically. No caller changes.
 */
#include "classifier.h"

/* ---- model hooks (WEAK STUBS , no trained models yet) -------------------------------------- */

__attribute__((weak)) bool clf_imu_model_present(void)   { return false; }
__attribute__((weak)) bool clf_audio_model_present(void) { return false; }

__attribute__((weak)) clf_result_t imu_model_infer(const imu_features_t *feat)
{
	(void)feat;
	return (clf_result_t){ .cls = CLF_UNKNOWN, .confidence = 0.0f };
}

__attribute__((weak)) clf_result_t audio_model_infer(const int16_t *pcm, size_t pcm_len)
{
	(void)pcm; (void)pcm_len;
	return (clf_result_t){ .cls = CLF_UNKNOWN, .confidence = 0.0f };
}

/* ---- cascade -------------------------------------------------------------------------------- */

static clf_config_t g_cfg = {
	.audio_confirm_enabled = true,    /* on while we build trust in the IMU model; flip off to save power */
	.conf_threshold        = 0.75f,   /* below this stage-1 confidence, consult audio (when enabled + present) */
};

void clf_init(void) { /* reserved for model / feature-extractor setup */ }

clf_config_t *clf_get_config(void) { return &g_cfg; }

clf_result_t clf_classify(const imu_features_t *feat, const int16_t *pcm, size_t pcm_len)
{
	/* Stage 1: IMU , cheap, always runs. Model-free this is UNKNOWN / 0. */
	clf_result_t r = imu_model_infer(feat);

	/* Stage 2: audio confirm , only when enabled AND a model is present AND stage 1 was unsure.
	 * This is the gate: a confident IMU result skips audio entirely, and with no audio model we
	 * simply keep the IMU result. */
	if (g_cfg.audio_confirm_enabled && clf_audio_model_present() &&
	    r.confidence < g_cfg.conf_threshold && pcm && pcm_len > 0) {
		clf_result_t a = audio_model_infer(pcm, pcm_len);
		if (a.confidence > r.confidence) {
			r = a;   /* trust the more-confident stage */
		}
	}
	return r;
}
```

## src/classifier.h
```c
/*
 * On-collar action classifier , the confidence-gated cascade.
 *
 * Stage 1 is the IMU model (cheap, always runs). Stage 2 is an optional audio confirm model that
 * only runs when (a) it's enabled, (b) a model is actually linked, and (c) the IMU stage was not
 * confident. So when the IMU is sure the audio stage never fires (it "disables itself"), and when
 * battery matters you can switch it off entirely with one config flag.
 *
 * IMPORTANT: there are no trained models yet. The inference hooks are weak stubs that return "no
 * prediction", so this whole pipeline compiles and runs model-free. Dropping a model in later means
 * providing a strong definition of the hook + flipping its *_present() to true , nothing else
 * changes. See classifier.c.
 */
#pragma once
#include <stdint.h>
#include <stdbool.h>
#include <stddef.h>

/* The cascade is action-agnostic: it reports a CLASS INDEX, not a fixed enum, so the same firmware
 * recognises whatever actions the model was trained on (eat / drink / purr / scratch / litter / ...).
 * `cls` indexes the active model's label table , the names live in the generated model metadata
 * (e.g. imu_labels[] / audio_labels[] from software/training), not hardcoded here. */
#define CLF_UNKNOWN (-1)   /* no confident prediction */

typedef struct {
	int   cls;          /* class index into the model's label table, or CLF_UNKNOWN */
	float confidence;   /* 0..1 */
} clf_result_t;

/* The raw IMU window handed to the stage-1 model. Interleaved int16 frames [ax,ay,az,gx,gy,gz];
 * accel in milli-g, gyro in centi-deg/s. The model's own front-end extracts features from this, so
 * we pass the raw window rather than a fixed feature vector. samples==NULL/count==0 means "no IMU
 * this cycle" (the stub model just returns UNKNOWN). */
typedef struct {
	const int16_t *samples;   /* count int16 values = frames * 6 */
	size_t         count;
	uint16_t       rate_hz;
	uint8_t        axes;      /* 6 (accel x/y/z + gyro x/y/z) */
} imu_features_t;

/* Runtime config for the cascade. Defaults are safe with no models present. These two are what a
 * future BLE config characteristic will set from the dashboard. */
typedef struct {
	bool  audio_confirm_enabled;   /* allow stage-2 audio confirm at all */
	float conf_threshold;          /* below this stage-1 confidence, consult audio (if enabled+present) */
} clf_config_t;

void          clf_init(void);
clf_config_t *clf_get_config(void);

/* Is a trained model actually linked for that stage? Both false until we drop models in. */
bool clf_imu_model_present(void);
bool clf_audio_model_present(void);

/* The confidence-gated cascade. Model-free this returns CLF_UNKNOWN / 0. `pcm`/`pcm_len` may be
 * NULL/0 when there's no audio for this cycle , the audio stage is skipped in that case anyway.
 *
 * AUDIO CONTRACT: `pcm` MUST be in the model's training representation , 8 kHz, µ-law-companded
 * 16-bit (MODEL_AUDIO_RATE_HZ). Always produce it by running live mic audio through
 * audio_to_model_pcm() in audio_codec.h; that is the exact transform training clips went through.
 * Do NOT pass raw 16 kHz or clean PCM here , a train/inference mismatch wrecks accuracy. */
clf_result_t clf_classify(const imu_features_t *feat, const int16_t *pcm, size_t pcm_len);
```
